# ATmega128RFA1 device description
Architecture: AVR8; Family: megaAVR
Registers are 8-bit, access not given, no defined reset value unless marked. A register's access mark holds for its fields unless they carry their own. Offsets are from the block's base; [hi:lo] are bit positions.

## SPI — Serial Peripheral Interface
Instances: SPI 0x00
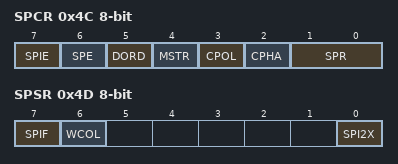
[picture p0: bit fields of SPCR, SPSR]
0x4C SPCR — SPI Control Register
  [7] SPIE — SPI Interrupt Enable
  [6] SPE — SPI Enable
  [5] DORD — Data Order
  [4] MSTR — Master/Slave Select
  [3] CPOL — Clock polarity
    0=Rising (Leading Edge), Falling (Trailing Edge); 1=Falling (Leading Egde), Rising (Trailing Edge)
  [2] CPHA — Clock Phase
    0=Sample (Leading Edge), Setup (Trailing Edge); 1=Setup (Leading Edge), Sample (Trailing Edge)
  [1:0] SPR — SPI Clock Rate Select 1 and 0
    0=fosc/4; 1=fosc/16; 2=fosc/64; 3=fosc/128; 4=fosc/2; 5=fosc/8; 6=fosc/32; 7=fosc/64
0x4D SPSR — SPI Status Register
  [7] SPIF — SPI Interrupt Flag
  [6] WCOL — Write Collision Flag
  [0] SPI2X — Double SPI Speed Bit
0x4E SPDR — SPI Data Register

## USART0_SPI — Serial Peripheral Interface
Instances: USART0_SPI 0x00
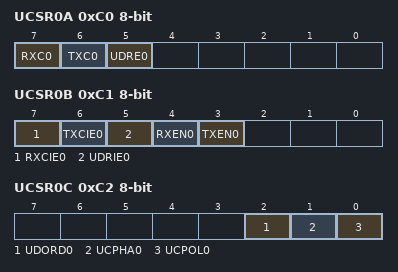
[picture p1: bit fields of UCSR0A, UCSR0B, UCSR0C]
0xC0 UCSR0A — USART0 MSPIM Control and Status Register A
  [7] RXC0 — USART Receive Complete
  [6] TXC0 — USART Transmit Complete
  [5] UDRE0 — USART Data Register Empty
0xC1 UCSR0B — USART0 MSPIM Control and Status Register B
  [7] RXCIE0 — RX Complete Interrupt Enable
  [6] TXCIE0 — TX Complete Interrupt Enable
  [5] UDRIE0 — USART Data Register Empty Interrupt Enable
  [4] RXEN0 — Receiver Enable
  [3] TXEN0 — Transmitter Enable
0xC2 UCSR0C — USART0 MSPIM Control and Status Register C
  [2] UDORD0 — Data Order
  [1] UCPHA0 — Clock Phase
  [0] UCPOL0 — Clock Polarity

## USART1_SPI — Serial Peripheral Interface
Instances: USART1_SPI 0x00
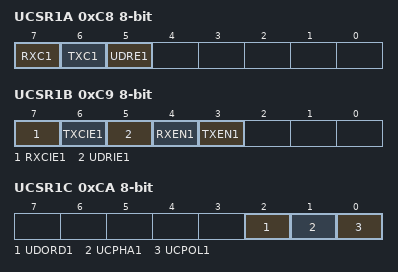
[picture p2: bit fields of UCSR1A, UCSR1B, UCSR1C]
0xC8 UCSR1A — USART1 MSPIM Control and Status Register A
  [7] RXC1 — USART Receive Complete
  [6] TXC1 — USART Transmit Complete
  [5] UDRE1 — USART Data Register Empty
0xC9 UCSR1B — USART1 MSPIM Control and Status Register B
  [7] RXCIE1 — RX Complete Interrupt Enable
  [6] TXCIE1 — TX Complete Interrupt Enable
  [5] UDRIE1 — USART Data Register Empty Interrupt Enable
  [4] RXEN1 — Receiver Enable
  [3] TXEN1 — Transmitter Enable
0xCA UCSR1C — USART1 MSPIM Control and Status Register C
  [2] UDORD1 — Data Order
  [1] UCPHA1 — Clock Phase
  [0] UCPOL1 — Clock Polarity

## PORTA — I/O Port
Instances: PORTA 0x00
0x20 PINA — Port A Input Pins Address
0x21 DDRA — Port A Data Direction Register
0x22 PORTA — Port A Data Register

## PORTB — I/O Port
Instances: PORTB 0x00
0x23 PINB — Port B Input Pins Address
0x24 DDRB — Port B Data Direction Register
0x25 PORTB — Port B Data Register

## PORTC — I/O Port
Instances: PORTC 0x00
0x26 PINC — Port C Input Pins Address
0x27 DDRC — Port C Data Direction Register
0x28 PORTC — Port C Data Register

## PORTD — I/O Port
Instances: PORTD 0x00
0x29 PIND — Port D Input Pins Address
0x2A DDRD — Port D Data Direction Register
0x2B PORTD — Port D Data Register

## PORTE — I/O Port
Instances: PORTE 0x00
0x2C PINE — Port E Input Pins Address
0x2D DDRE — Port E Data Direction Register
0x2E PORTE — Port E Data Register

## PORTF — I/O Port
Instances: PORTF 0x00
0x2F PINF — Port F Input Pins Address
0x30 DDRF — Port F Data Direction Register
0x31 PORTF — Port F Data Register

## PORTG — I/O Port
Instances: PORTG 0x00
0x32 PING — Port G Input Pins Address
0x33 DDRG — Port G Data Direction Register
0x34 PORTG — Port G Data Register

## TC0 (TC8 module) — Timer/Counter, 8-bit
Instances: TC0 0x00
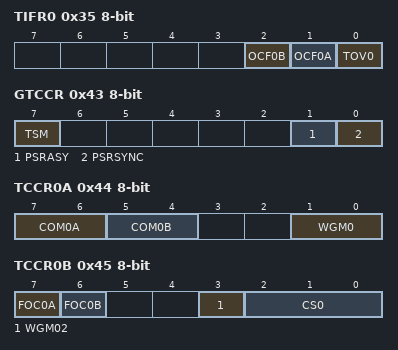
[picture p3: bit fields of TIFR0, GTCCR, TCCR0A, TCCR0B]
0x35 TIFR0 — Timer/Counter0 Interrupt Flag Register
  [2] OCF0B — Timer/Counter0 Output Compare B Match Flag
  [1] OCF0A — Timer/Counter0 Output Compare A Match Flag
  [0] TOV0 — Timer/Counter0 Overflow Flag
0x43 GTCCR — General Timer/Counter Control Register
  [7] TSM — Timer/Counter Synchronization Mode
  [1] PSRASY — Prescaler Reset Timer/Counter2
  [0] PSRSYNC — Prescaler Reset for Synchronous Timer/Counters
0x44 TCCR0A — Timer/Counter0 Control Register A
  [7:6] COM0A — Compare Match Output A Mode
    0=Normal port operation, OC0A disconnected; 1=Toggle OC0A on Compare Match; 2=Clear OC0A on Compare Match; 3=Set OC0A on Compare Match
  [5:4] COM0B — Compare Match Output B Mode
    0=Normal port operation, OC0B disconnected; 1=Toggle OC0B on Compare Match; 2=Clear OC0B on Compare Match; 3=Set OC0B on Compare Match
  [1:0] WGM0 — Waveform Generation Mode
    0=Normal mode of operation; 1=PWM, phase correct, TOP=0xFF; 2=CTC, TOP = OCRA; 3=Fast PWM, TOP=0xFF; 5=PWM, Phase correct, TOP = OCRA; 7=Fast PWM, TOP=OCRA
0x45 TCCR0B — Timer/Counter0 Control Register B
  [7] FOC0A — Force Output Compare A
  [6] FOC0B — Force Output Compare B
  [3] WGM02
  [2:0] CS0 — Clock Select
    0=No clock source (Timer/Counter0 stopped); 1=clk_IO/1 (no prescaling); 2=clk_IO/8 (from prescaler); 3=clk_IO/64 (from prescaler); 4=clk_IO/256 (from prescaler); 5=clk_IO/1024 (from prescaler); 6=External clock source on T0 pin, clock on falling edge; 7=External clock source on T0 pin, clock on rising edge
0x46 TCNT0 — Timer/Counter0 Register
0x47 OCR0A — Timer/Counter0 Output Compare Register
0x48 OCR0B — Timer/Counter0 Output Compare Register B
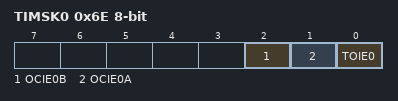
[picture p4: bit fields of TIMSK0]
0x6E TIMSK0 — Timer/Counter0 Interrupt Mask Register
  [2] OCIE0B — Timer/Counter0 Output Compare Match B Interrupt Enable
  [1] OCIE0A — Timer/Counter0 Output Compare Match A Interrupt Enable
  [0] TOIE0 — Timer/Counter0 Overflow Interrupt Enable
